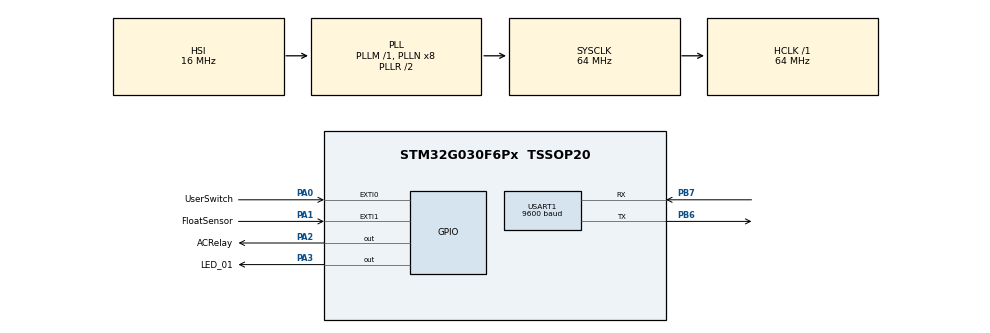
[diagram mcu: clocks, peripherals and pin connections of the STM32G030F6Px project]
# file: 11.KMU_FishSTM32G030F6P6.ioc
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Mcu.Family=STM32G0
Mcu.Name=STM32G030F6Px
Mcu.Package=TSSOP20
NVIC.USART1_IRQn=true\:0\:0\:true\:false\:true\:true\:true\:true
PA0.GPIO_Label=UserSwitch
PA0.GPIO_ModeDefaultEXTI=GPIO_MODE_EVT_RISING
PA0.GPIO_PuPd=GPIO_NOPULL
PA0.Signal=GPXTI0
PA1.GPIO_Label=FloatSensor
PA1.GPIO_ModeDefaultEXTI=GPIO_MODE_EVT_RISING
PA1.GPIO_PuPd=GPIO_NOPULL
PA1.Signal=GPXTI1
PA13.Mode=Serial_Wire
PA13.Signal=SYS_SWDIO
PA14-BOOT0.Mode=Serial_Wire
PA14-BOOT0.Signal=SYS_SWCLK
PA14-BOOT0__PA15.StandardMode=true
PA2.GPIO_Label=ACRelay
PA2.GPIO_ModeDefaultOutputPP=GPIO_MODE_OUTPUT_PP
PA2.GPIO_PuPd=GPIO_NOPULL
PA2.PinState=GPIO_PIN_RESET
PA2.Signal=GPIO_Output
PA3.GPIO_Label=LED_01
PA3.GPIO_ModeDefaultOutputPP=GPIO_MODE_OUTPUT_PP
PA3.GPIO_PuPd=GPIO_NOPULL
PA3.Signal=GPIO_Output
PB0__PB1__PB2__PA8.StandardMode=true
PB3__PB4__PB5__PB6.StandardMode=true
PB6.Mode=Asynchronous
PB6.Signal=USART1_TX
PB7.Mode=Asynchronous
PB7.Signal=USART1_RX
PB7__PB8.StandardMode=true
PC14-OSC32_IN\ (PC14).Mode=LSE-External-Oscillator
PC14-OSC32_IN\ (PC14).Signal=RCC_OSC32_IN
PC14-OSC32_IN\ (PC14)__PB9.StandardMode=true
PC15-OSC32_OUT\ (PC15).Mode=LSE-External-Oscillator
PC15-OSC32_OUT\ (PC15).Signal=RCC_OSC32_OUT
ProjectManager.HeapSize=0x200
ProjectManager.StackSize=0x400
ProjectManager.TargetToolchain=STM32CubeIDE
RCC.ADCFreq_Value=64000000
RCC.AHBFreq_Value=64000000
RCC.CortexFreq_Value=64000000
RCC.EXTERNAL_CLOCK_VALUE=12288000
RCC.HCLKFreq_Value=64000000
RCC.HSE_VALUE=8000000
RCC.HSI_VALUE=16000000
RCC.SYSCLKFreq_VALUE=64000000
RCC.SYSCLKSource=RCC_SYSCLKSOURCE_PLLCLK
RCC.VCOOutputFreq_Value=128000000
TIM14.Prescaler=64-1
USART1.BaudRate=9600
USART1.Mode=MODE_TX_RX
USART1.VirtualMode-Asynchronous=VM_ASYNC
VP_TIM14_VS_ClockSourceINT.Mode=Enable_Timer
board=custom

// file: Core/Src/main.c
/* USER CODE BEGIN Header */
/**
  ******************************************************************************
  * @file           : main.c
  * @brief          : Main program body
  ******************************************************************************
  * @attention
  *
  * Copyright (c) 2025 STMicroelectronics.
  * All rights reserved.
  *
  * This software is licensed under terms that can be found in the LICENSE file
  * in the root directory of this software component.
  * If no LICENSE file comes with this software, it is provided AS-IS.
  *
  ******************************************************************************
  */
/* USER CODE END Header */
#include "main.h"
#include "tim.h"
#include "usart.h"
#include "gpio.h"

/* USER CODE BEGIN Includes */
#include "app_fish_tank.h"
/* USER CODE END Includes */

void SystemClock_Config(void);

int main(void)
{
  /* MCU Configuration--------------------------------------------------------*/

  /* Reset of all peripherals, Initializes the Flash interface and the Systick. */
  HAL_Init();

  /* Configure the system clock */
  SystemClock_Config();

  /* Initialize all configured peripherals */
  MX_GPIO_Init();
  MX_USART1_UART_Init();
  MX_TIM14_Init();

  /* USER CODE BEGIN 2 */
  App_Init();
  /* USER CODE END 2 */

  /* Infinite loop */
  /* USER CODE BEGIN WHILE */
  while (1)
  {
    App_Process();
    /* USER CODE END WHILE */

  }
}

void SystemClock_Config(void)
{
  RCC_OscInitTypeDef RCC_OscInitStruct = {0};
  RCC_ClkInitTypeDef RCC_ClkInitStruct = {0};

  /** Configure the main internal regulator output voltage
  */
  HAL_PWREx_ControlVoltageScaling(PWR_REGULATOR_VOLTAGE_SCALE1);

  /** Initializes the RCC Oscillators according to the specified parameters
  * in the RCC_OscInitTypeDef structure.
  */
  RCC_OscInitStruct.OscillatorType = RCC_OSCILLATORTYPE_HSI;
  RCC_OscInitStruct.HSIState = RCC_HSI_ON;
  RCC_OscInitStruct.HSIDiv = RCC_HSI_DIV1;
  RCC_OscInitStruct.HSICalibrationValue = RCC_HSICALIBRATION_DEFAULT;
  RCC_OscInitStruct.PLL.PLLState = RCC_PLL_ON;
  RCC_OscInitStruct.PLL.PLLSource = RCC_PLLSOURCE_HSI;
  RCC_OscInitStruct.PLL.PLLM = RCC_PLLM_DIV1;
  RCC_OscInitStruct.PLL.PLLN = 8;
  RCC_OscInitStruct.PLL.PLLP = RCC_PLLP_DIV2;
  RCC_OscInitStruct.PLL.PLLR = RCC_PLLR_DIV2;
  if (HAL_RCC_OscConfig(&RCC_OscInitStruct) != HAL_OK)
  {
    Error_Handler();
  }

  /** Initializes the CPU, AHB and APB buses clocks
  */
  RCC_ClkInitStruct.ClockType = RCC_CLOCKTYPE_HCLK|RCC_CLOCKTYPE_SYSCLK
                              |RCC_CLOCKTYPE_PCLK1;
  RCC_ClkInitStruct.SYSCLKSource = RCC_SYSCLKSOURCE_PLLCLK;
  RCC_ClkInitStruct.AHBCLKDivider = RCC_SYSCLK_DIV1;
  RCC_ClkInitStruct.APB1CLKDivider = RCC_HCLK_DIV1;

  if (HAL_RCC_ClockConfig(&RCC_ClkInitStruct, FLASH_LATENCY_2) != HAL_OK)
  {
    Error_Handler();
  }
}

void Error_Handler(void)
{
  __disable_irq();
  while (1)
  {
  }
}
